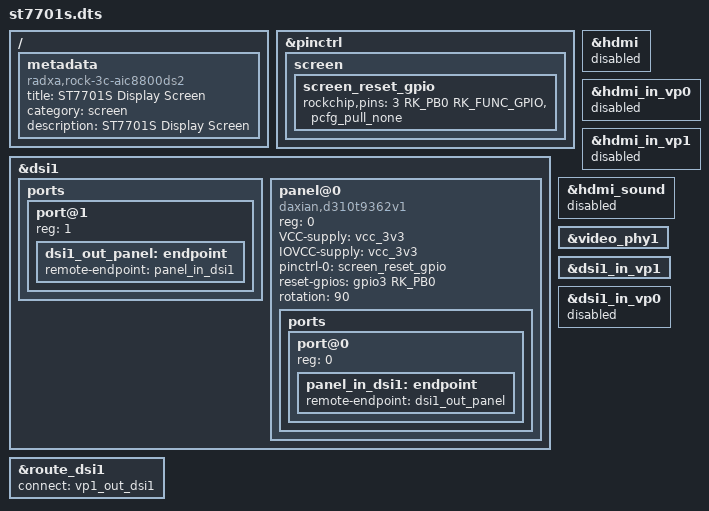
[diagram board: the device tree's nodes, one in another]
/dts-v1/;
/plugin/;

#include <dt-bindings/gpio/gpio.h>
#include <dt-bindings/pinctrl/rockchip.h>
#include <dt-bindings/display/rockchip_vop.h>

/ {
    metadata {
        title = "ST7701S Display Screen";
        compatible = "radxa,rock-3c-aic8800ds2", "radxa,rock-3c", "rockchip,rk3566";
        category = "screen";
        description = "ST7701S Display Screen";
    };

    fragment@0 {
        target = <&pinctrl>;
        __overlay__ {
            screen {
                screen_reset_gpio: screen_reset_gpio {
                    rockchip,pins = <3 RK_PB0 RK_FUNC_GPIO &pcfg_pull_none>;
                };
            };
        };
    };

    fragment@1 {
        target = <&dsi1>;
        __overlay__ {
            status = "okay";
            #address-cells = <0x01>;
			#size-cells = <0x00>;

            ports {
                #address-cells = <0x01>;
			    #size-cells = <0x00>;
                port@1 {
                    reg = <1>;
                    dsi1_out_panel: endpoint {
                        remote-endpoint = <&panel_in_dsi1>;
                    };
                };
            };

           panel@0 {
                status = "okay";
                // compatible = "techstar,ts8550b", "sitronix,st7701";
                // compatible = "simple-panel";
                compatible = "daxian,d310t9362v1";
                reg = <0>;
                VCC-supply = <&vcc_3v3>;
                IOVCC-supply = <&vcc_3v3>;
                pinctrl-names = "default";
                pinctrl-0 = <&screen_reset_gpio>;
                reset-gpios = <&gpio3 RK_PB0 GPIO_ACTIVE_HIGH>;
                rotation = <90>;

                ports {
                    #address-cells = <0x01>;
			        #size-cells = <0x00>;
                    port@0 {
                        reg = <0>;
                        panel_in_dsi1: endpoint {
                            status = "okay";
                            remote-endpoint = <&dsi1_out_panel>;
                        };
                    };
                };
            };
        };
    };

    fragment@2 {
        target = <&hdmi>;
        __overlay__ {
            status = "disabled";
        };
    };

    fragment@3 {
        target = <&hdmi_in_vp0>;
        __overlay__ {
            status = "disabled";
        };
    };

    fragment@4 {
        target = <&hdmi_in_vp1>;
        __overlay__ {
            status = "disabled";
        };
    };

    fragment@5 {
        target = <&hdmi_sound>;
        __overlay__ {
            status = "disabled";
        };
    };

    fragment@6 {
        target = <&video_phy1>;
        __overlay__ {
            status = "okay";
        };
    };

    fragment@7 {
        target = <&route_dsi1>;
        __overlay__ {
            status = "okay";
            connect = <&vp1_out_dsi1>;
        };
    };

    fragment@8 {
        target = <&dsi1_in_vp1>;
        __overlay__ {
            status = "okay";
        };
    };

    fragment@9 {
        target = <&dsi1_in_vp0>;
        __overlay__ {
            status = "disabled";
        };
    };
};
